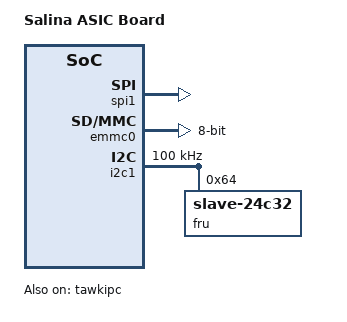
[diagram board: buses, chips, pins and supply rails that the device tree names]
// SPDX-License-Identifier: (GPL-2.0-only or BSD-2-Clause)
/*
 * Device Tree file for AMD Pensando Salina Board.
 *
 * Copyright 2023-2024 Advanced Micro Devices, Inc.
 */

/dts-v1/;

#include "salina-asic.dtsi"
#include "salina-16core.dtsi"
#include "salina-n1-common.dtsi"
#include "salina-n1-flash-parts.dtsi"
#include "elba-asic-memory.dtsi"
#include "elba-mdev.dtsi"

/ {
	model = "Salina ASIC Board";
	compatible = "pensando,salina";

	aliases {
		serial1 = &uart1;
		spi1 = &spi1;
	};

	chosen {
		stdout-path = "serial1:115200n8";
	};

	tawkipc {
		compatible = "amd,tawk-ipc";
		peer-id = <1>;
		#address-cells = <2>;
		#size-cells = <1>;
		reg = <0x0 0x0 0x0 0x0>,  /* doorbells */
			<0x0 0x0 0x0 0x0>, /* msix-like table */
			<0x47 0xe1d2b100 0x0 0x8>,  /* reset signal registers */
			<0x47 0xe1d2c100 0x0 0x10>,     /* mailbox control registers */
			<0x47 0xe1d2d100 0x0 0x800>;    /* mailbox buffers */
		rst-sigs = <0x4 0x0>;
		nmboxes = <2>;
		mbox-ctl = <0x0 0x3>;
		mbox-buf = <0x0 0xa 0x400>;
		status = "okay";
	};
};

&spi1 {
	status = "okay";
};

&emmc_clk {
	clock-frequency = <208000000>;
};

&emmc0 {
	bus-width = <8>;
	cap-mmc-hw-reset;
	reset-names = "hw";
	resets = <&rstc 0>;
	status = "ok";
};

&i2c1 {
	clock-frequency = <100000>;
	status = "okay";

	fru@64 {
		compatible = "slave-24c32";
		reg = <0x64>;
	};
};

&soc {
	rstc: reset-controller@0 {
		compatible = "amd,pensando-salinasr-reset";
		reg = <0x0 0x0 0x0 0xff>;
		#reset-cells = <1>;
	};
};
